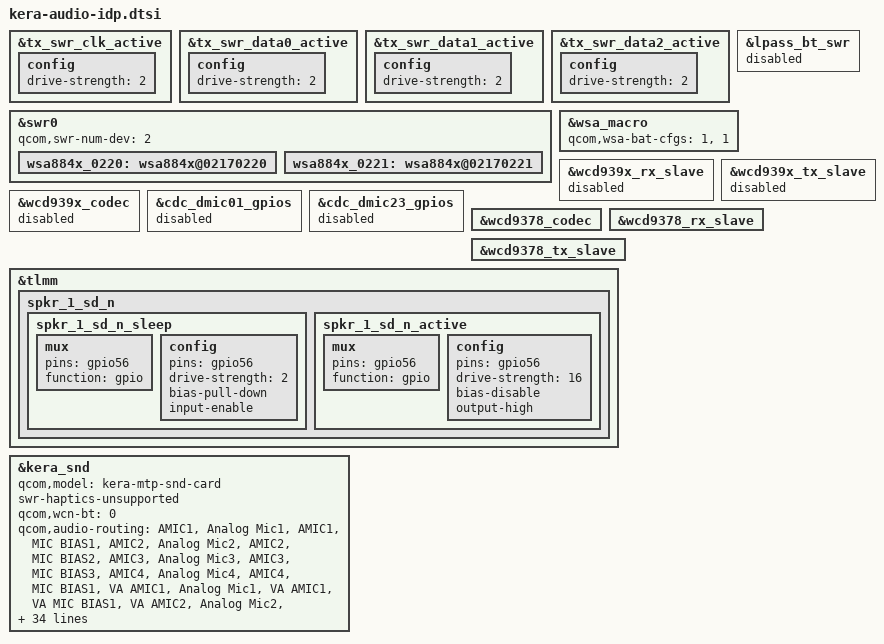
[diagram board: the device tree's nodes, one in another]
// SPDX-License-Identifier: BSD-3-Clause
/*
 * Copyright (c) Qualcomm Technologies, Inc. and/or its subsidiaries.
 */
#include "kera-audio-overlay.dtsi"
#include "kera-audio-lpass-reg.dtsi"

&tx_swr_clk_active {
	config {
		drive-strength = <2>;
	};
};

&tx_swr_data0_active {
	config {
		drive-strength = <2>;
	};
};

&tx_swr_data1_active {
	config {
		drive-strength = <2>;
	};
};

&tx_swr_data2_active {
	config {
		drive-strength = <2>;
	};
};

&swr0 {
	qcom,swr-num-dev = <2>;
	wsa884x_0220: wsa884x@02170220 {
		status = "okay";
	};

	wsa884x_0221: wsa884x@02170221 {
		status = "okay";
	};
};

&lpass_bt_swr {
	status = "disabled";
};

&wsa_macro {
	qcom,wsa-bat-cfgs = <1>, <1>;
};

&wcd939x_rx_slave {
	status = "disabled";
};

&wcd939x_tx_slave {
	status = "disabled";
};

&wcd939x_codec {
	status = "disabled";
};

&cdc_dmic01_gpios {
	status = "disabled";
};

&cdc_dmic23_gpios {
	status = "disabled";
};

&wcd9378_codec {
	status = "okay";
};

&wcd9378_rx_slave {
	status = "okay";
};

&wcd9378_tx_slave {
	status = "okay";
};

&tlmm {
	spkr_1_sd_n {
		spkr_1_sd_n_sleep: spkr_1_sd_n_sleep {
			mux {
				pins = "gpio56";
				function = "gpio";
			};

			config {
				pins = "gpio56";
				drive-strength = <2>;   /* 2 mA */
				bias-pull-down;
				input-enable;
			};
		};

		spkr_1_sd_n_active: spkr_1_sd_n_active {
			mux {
				pins = "gpio56";
				function = "gpio";
			};

			config {
				pins = "gpio56";
				drive-strength = <16>;   /* 16 mA */
				bias-disable;
				output-high;
			};
		};
	};
};

&kera_snd {
	qcom,model = "kera-mtp-snd-card";
	swr-haptics-unsupported;
	qcom,wcn-bt = <0>;
		qcom,audio-routing =
			"AMIC1", "Analog Mic1",
			"AMIC1", "MIC BIAS1",
			"AMIC2", "Analog Mic2",
			"AMIC2", "MIC BIAS2",
			"AMIC3", "Analog Mic3",
			"AMIC3", "MIC BIAS3",
			"AMIC4", "Analog Mic4",
			"AMIC4", "MIC BIAS1",
			"VA AMIC1", "Analog Mic1",
			"VA AMIC1", "VA MIC BIAS1",
			"VA AMIC2", "Analog Mic2",
			"VA AMIC2", "VA MIC BIAS2",
			"VA AMIC3", "Analog Mic3",
			"VA AMIC3", "VA MIC BIAS3",
			"VA AMIC4", "Analog Mic4",
			"VA AMIC4", "VA MIC BIAS1",
			"TX DMIC0", "Digital Mic0",
			"TX DMIC0", "MIC BIAS3",
			"TX DMIC1", "Digital Mic1",
			"TX DMIC1", "MIC BIAS3",
			"TX DMIC2", "Digital Mic2",
			"TX DMIC2", "MIC BIAS1",
			"TX DMIC3", "Digital Mic3",
			"TX DMIC3", "MIC BIAS1",
			"IN1_HPHL", "HPHL_OUT",
			"IN2_HPHR", "HPHR_OUT",
			"IN3_AUX", "AUX_OUT",
			"WSA SRC0_INP", "SRC0",
			"WSA_TX DEC0_INP", "TX DEC0 MUX",
			"WSA_TX DEC1_INP", "TX DEC1 MUX",
			"RX_TX DEC0_INP", "TX DEC0 MUX",
			"RX_TX DEC1_INP", "TX DEC1 MUX",
			"RX_TX DEC2_INP", "TX DEC2 MUX",
			"RX_TX DEC3_INP", "TX DEC3 MUX",
			"SpkrLeft IN", "WSA_SPK1 OUT",
			"SpkrRight IN", "WSA_SPK2 OUT",
			"VA SWR_INPUT", "VA_SWR_CLK",
			"VA_AIF1 CAP", "VA_SWR_CLK",
			"VA_AIF2 CAP", "VA_SWR_CLK",
			"VA_AIF3 CAP", "VA_SWR_CLK",
			"VA DMIC0", "Digital Mic0",
			"VA DMIC1", "Digital Mic1",
			"VA DMIC2", "Digital Mic2",
			"VA DMIC3", "Digital Mic3",
			"VA DMIC0", "VA MIC BIAS3",
			"VA DMIC1", "VA MIC BIAS3",
			"VA DMIC2", "VA MIC BIAS1",
			"VA DMIC3", "VA MIC BIAS1";
	asoc-codec  = <&stub_codec>, <&lpass_cdc>,
			<&wcd9378_codec>, <&wsa884x_0220>, <&wsa884x_0221>;
	asoc-codec-names = "msm-stub-codec.1", "lpass-cdc",
			"wcd9378_codec", "wsa-codec1", "wsa-codec2";
	qcom,msm_audio_ssr_devs = <&audio_gpr>, <&lpi_tlmm>,
				  <&lpass_cdc>;
	qcom,wsa-max-devs = <2>;
	qcom,msm-mbhc-hphl-swh = <1>;
	qcom,msm-mbhc-gnd-swh = <1>;
	qcom,msm-mbhc-usbc-audio-supported = <0>;
	fsa4480-i2c-handle = <&fsa4480>;
};
